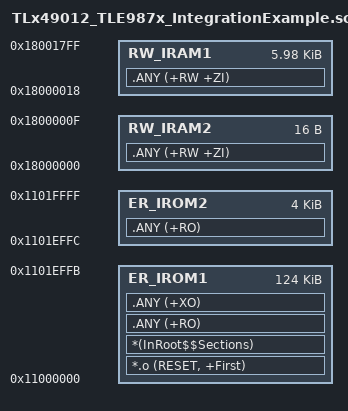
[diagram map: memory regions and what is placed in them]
; *************************************************************
; *** Scatter-Loading Description File generated by uVision ***
; *************************************************************

LR_IROM1 0x11000000 0x0001EFFC  {    ; load region size_region
  ER_IROM1 0x11000000 0x0001EFFC  {  ; load address = execution address
   *.o (RESET, +First)
   *(InRoot$$Sections)
   .ANY (+RO)
   .ANY (+XO)
  }
  RW_IRAM1 0x18000018 0x000017E8  {  ; RW data
   .ANY (+RW +ZI)
  }
  RW_IRAM2 0x18000000 0x00000010  {
   .ANY (+RW +ZI)
  }
}

LR_IROM2 0x1101EFFC 0x00001004  {
  ER_IROM2 0x1101EFFC 0x00001004  {  ; load address = execution address
   .ANY (+RO)
  }
}
